AUTOSAR XML (schema 00046)
package /ComponentTypes
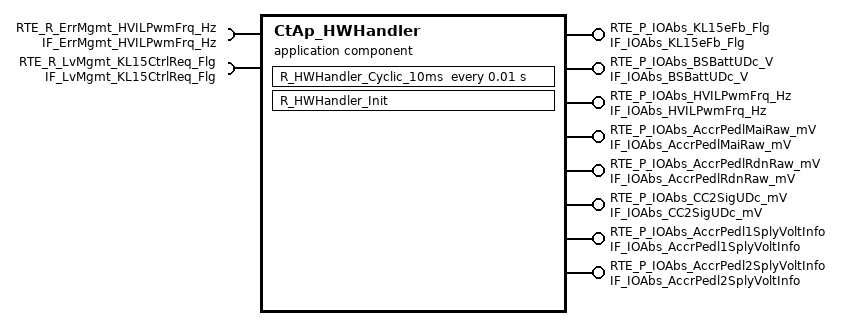
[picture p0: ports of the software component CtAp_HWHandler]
  application sw component type CtAp_HWHandler
    6 x provide port:
      RTE_P_IOAbs_KL15eFb_Flg: nonqueued-sender-com-spec{data-element=tec_IOAbs_KL15eFb_Flg, init-value=0}, provided-interface=IF_IOAbs_KL15eFb_Flg
      RTE_P_IOAbs_BSBattUDc_V: nonqueued-sender-com-spec{data-element=tec_IOAbs_BSBattUDc_V, init-value=0}, provided-interface=IF_IOAbs_BSBattUDc_V
      RTE_P_IOAbs_HVILPwmFrq_Hz: nonqueued-sender-com-spec{data-element=tec_IOAbs_HVILPwmFrq_Hz, init-value=0}, provided-interface=IF_IOAbs_HVILPwmFrq_Hz
      RTE_P_IOAbs_AccrPedlMaiRaw_mV: nonqueued-sender-com-spec{data-element=tec_IOAbs_AccrPedlMaiRaw_mV, init-value=0}, provided-interface=IF_IOAbs_AccrPedlMaiRaw_mV
      RTE_P_IOAbs_AccrPedlRdnRaw_mV: nonqueued-sender-com-spec{data-element=tec_IOAbs_AccrPedlRdnRaw_mV, init-value=0}, provided-interface=IF_IOAbs_AccrPedlRdnRaw_mV
      RTE_P_IOAbs_CC2SigUDc_mV: nonqueued-sender-com-spec{data-element=tec_IOAbs_CC2SigUDc_mV, init-value=0}, provided-interface=IF_IOAbs_CC2SigUDc_mV
    require port RTE_R_ErrMgmt_HVILPwmFrq_Hz: nonqueued-receiver-com-spec{data-element=tec_ErrMgmt_HVILPwmFrq_Hz, filter=data-filter-type=ALWAYS, init-value=0}, required-interface=IF_ErrMgmt_HVILPwmFrq_Hz
    require port RTE_R_LvMgmt_KL15CtrlReq_Flg: nonqueued-receiver-com-spec{data-element=tec_LvMgmt_KL15CtrlReq_Flg, filter=data-filter-type=ALWAYS, init-value=0}, required-interface=IF_LvMgmt_KL15CtrlReq_Flg
    provide port RTE_P_IOAbs_AccrPedl1SplyVoltInfo: nonqueued-sender-com-spec{data-element=tec_IOAbs_AccrPedl1SplyVoltInfo, init-value=0}, provided-interface=IF_IOAbs_AccrPedl1SplyVoltInfo
    provide port RTE_P_IOAbs_AccrPedl2SplyVoltInfo: nonqueued-sender-com-spec{data-element=tec_IOAbs_AccrPedl2SplyVoltInfo, init-value=0}, provided-interface=IF_IOAbs_AccrPedl2SplyVoltInfo
    behavior CtAp_HWHandler_InternalBehavior
      timing event TMT_R_HWHandler_Cyclic_10ms: start-on-event=R_HWHandler_Cyclic_10ms, period=0.01
      init event CtAp_HWHandler_InitEvent: start-on-event=R_HWHandler_Init
      runnable R_HWHandler_Cyclic_10ms
        data-receive-point-by-arguments:
          access REC_RTE_R_ErrMgmt_HVILPwmFrq_Hz_tec_ErrMgmt_HVILPwmFrq_Hz: accessed-variable=RTE_R_ErrMgmt_HVILPwmFrq_Hz.tec_ErrMgmt_HVILPwmFrq_Hz
          access REC_RTE_R_LvMgmt_KL15CtrlReq_Flg_tec_LvMgmt_KL15CtrlReq_Flg: accessed-variable=RTE_R_LvMgmt_KL15CtrlReq_Flg.tec_LvMgmt_KL15CtrlReq_Flg
        data-send-points:
          8 x access:
            SEND_RTE_P_IOAbs_AccrPedlMaiRaw_mV_tec_IOAbs_AccrPedlMaiRaw_mV: accessed-variable=RTE_P_IOAbs_AccrPedlMaiRaw_mV.tec_IOAbs_AccrPedlMaiRaw_mV
            SEND_RTE_P_IOAbs_AccrPedlRdnRaw_mV_tec_IOAbs_AccrPedlRdnRaw_mV: accessed-variable=RTE_P_IOAbs_AccrPedlRdnRaw_mV.tec_IOAbs_AccrPedlRdnRaw_mV
            SEND_RTE_P_IOAbs_BSBattUDc_V_tec_IOAbs_BSBattUDc_V: accessed-variable=RTE_P_IOAbs_BSBattUDc_V.tec_IOAbs_BSBattUDc_V
            SEND_RTE_P_IOAbs_CC2SigUDc_mV_tec_IOAbs_CC2SigUDc_mV: accessed-variable=RTE_P_IOAbs_CC2SigUDc_mV.tec_IOAbs_CC2SigUDc_mV
            SEND_RTE_P_IOAbs_HVILPwmFrq_Hz_tec_IOAbs_HVILPwmFrq_Hz: accessed-variable=RTE_P_IOAbs_HVILPwmFrq_Hz.tec_IOAbs_HVILPwmFrq_Hz
            SEND_RTE_P_IOAbs_KL15eFb_Flg_tec_IOAbs_KL15eFb_Flg: accessed-variable=RTE_P_IOAbs_KL15eFb_Flg.tec_IOAbs_KL15eFb_Flg
            SEND_RTE_P_IOAbs_AccrPedl1SplyVoltInfo_tec_IOAbs_AccrPedl1SplyVoltInfo: accessed-variable=RTE_P_IOAbs_AccrPedl1SplyVoltInfo.tec_IOAbs_AccrPedl1SplyVoltInfo
            SEND_RTE_P_IOAbs_AccrPedl2SplyVoltInfo_tec_IOAbs_AccrPedl2SplyVoltInfo: accessed-variable=RTE_P_IOAbs_AccrPedl2SplyVoltInfo.tec_IOAbs_AccrPedl2SplyVoltInfo
      runnable R_HWHandler_Init
  swc implementation CtAp_HWHandler_Implementation: behavior=CtAp_HWHandler_InternalBehavior
